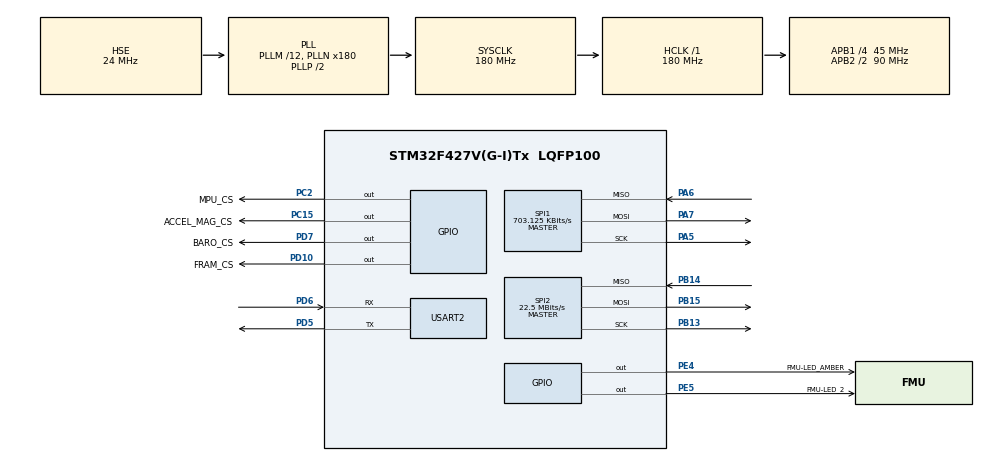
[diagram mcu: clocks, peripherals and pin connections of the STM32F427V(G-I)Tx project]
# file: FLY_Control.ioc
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Mcu.Family=STM32F4
Mcu.Name=STM32F427V(G-I)Tx
Mcu.Package=LQFP100
NVIC.PriorityGroup=NVIC_PRIORITYGROUP_4
PA13.Mode=Serial_Wire
PA13.Signal=SYS_JTMS-SWDIO
PA14.Mode=Serial_Wire
PA14.Signal=SYS_JTCK-SWCLK
PA5.Mode=Full_Duplex_Master
PA5.Signal=SPI1_SCK
PA6.Mode=Full_Duplex_Master
PA6.Signal=SPI1_MISO
PA7.Mode=Full_Duplex_Master
PA7.Signal=SPI1_MOSI
PB13.Mode=Full_Duplex_Master
PB13.Signal=SPI2_SCK
PB14.Mode=Full_Duplex_Master
PB14.Signal=SPI2_MISO
PB15.Mode=Full_Duplex_Master
PB15.Signal=SPI2_MOSI
PC15/OSC32_OUT.GPIO_Label=ACCEL_MAG_CS
PC15/OSC32_OUT.Signal=GPIO_Output
PC2.GPIO_Label=MPU_CS
PC2.GPIO_Speed=GPIO_SPEED_FREQ_HIGH
PC2.Signal=GPIO_Output
PD10.GPIO_Label=FRAM_CS
PD10.GPIO_Speed=GPIO_SPEED_FREQ_HIGH
PD10.Signal=GPIO_Output
PD5.Mode=Asynchronous
PD5.Signal=USART2_TX
PD6.Mode=Asynchronous
PD6.Signal=USART2_RX
PD7.GPIO_Label=BARO_CS
PD7.GPIO_Speed=GPIO_SPEED_FREQ_HIGH
PD7.Signal=GPIO_Output
PE4.GPIO_Label=FMU-LED_AMBER
PE4.GPIO_PuPd=GPIO_NOPULL
PE4.Signal=GPIO_Output
PE5.GPIO_Label=FMU-LED_2
PE5.Signal=GPIO_Output
PH0/OSC_IN.Mode=HSE-External-Clock-Source
PH0/OSC_IN.Signal=RCC_OSC_IN
PH1/OSC_OUT.Mode=HSE-External-Clock-Source
PH1/OSC_OUT.Signal=RCC_OSC_OUT
ProjectManager.HeapSize=0x200
ProjectManager.StackSize=0x400
ProjectManager.TargetToolchain=MDK-ARM V5
RCC.48MHZClocksFreq_Value=90000000
RCC.AHBFreq_Value=180000000
RCC.APB1CLKDivider=RCC_HCLK_DIV4
RCC.APB1Freq_Value=45000000
RCC.APB1TimFreq_Value=90000000
RCC.APB2CLKDivider=RCC_HCLK_DIV2
RCC.APB2Freq_Value=90000000
RCC.APB2TimFreq_Value=180000000
RCC.CortexFreq_Value=180000000
RCC.HCLKFreq_Value=180000000
RCC.HSE_VALUE=24000000
RCC.HSI_VALUE=16000000
RCC.LSE_VALUE=32768
RCC.PLLM=12
RCC.PLLN=180
RCC.PLLSourceVirtual=RCC_PLLSOURCE_HSE
RCC.SYSCLKFreq_VALUE=180000000
RCC.SYSCLKSource=RCC_SYSCLKSOURCE_PLLCLK
RCC.VCOOutputFreq_Value=360000000
SPI1.BaudRatePrescaler=SPI_BAUDRATEPRESCALER_128
SPI1.CalculateBaudRate=703.125 KBits/s
SPI1.Direction=SPI_DIRECTION_2LINES
SPI1.Mode=SPI_MODE_MASTER
SPI1.VirtualType=VM_MASTER
SPI2.CalculateBaudRate=22.5 MBits/s
SPI2.Direction=SPI_DIRECTION_2LINES
SPI2.Mode=SPI_MODE_MASTER
SPI2.VirtualType=VM_MASTER
USART2.VirtualMode=VM_ASYNC
board=FLY_Control

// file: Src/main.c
/**
  ******************************************************************************
  * File Name          : main.c
  * Description        : Main program body
  ******************************************************************************
  ** This notice applies to any and all portions of this file
  * that are not between comment pairs USER CODE BEGIN and
  * USER CODE END. Other portions of this file, whether
  * inserted by the user or by software development tools
  * are owned by their respective copyright owners.
  *
  * COPYRIGHT(c) 2019 STMicroelectronics
  *
  * Redistribution and use in source and binary forms, with or without modification,
  * are permitted provided that the following conditions are met:
  *   1. Redistributions of source code must retain the above copyright notice,
  *      this list of conditions and the following disclaimer.
  *   2. Redistributions in binary form must reproduce the above copyright notice,
  *      this list of conditions and the following disclaimer in the documentation
  *      and/or other materials provided with the distribution.
  *   3. Neither the name of STMicroelectronics nor the names of its contributors
  *      may be used to endorse or promote products derived from this software
  *      without specific prior written permission.
  *
  * THIS SOFTWARE IS PROVIDED BY THE COPYRIGHT HOLDERS AND CONTRIBUTORS "AS IS"
  * AND ANY EXPRESS OR IMPLIED WARRANTIES, INCLUDING, BUT NOT LIMITED TO, THE
  * IMPLIED WARRANTIES OF MERCHANTABILITY AND FITNESS FOR A PARTICULAR PURPOSE ARE
  * DISCLAIMED. IN NO EVENT SHALL THE COPYRIGHT HOLDER OR CONTRIBUTORS BE LIABLE
  * FOR ANY DIRECT, INDIRECT, INCIDENTAL, SPECIAL, EXEMPLARY, OR CONSEQUENTIAL
  * DAMAGES (INCLUDING, BUT NOT LIMITED TO, PROCUREMENT OF SUBSTITUTE GOODS OR
  * SERVICES; LOSS OF USE, DATA, OR PROFITS; OR BUSINESS INTERRUPTION) HOWEVER
  * CAUSED AND ON ANY THEORY OF LIABILITY, WHETHER IN CONTRACT, STRICT LIABILITY,
  * OR TORT (INCLUDING NEGLIGENCE OR OTHERWISE) ARISING IN ANY WAY OUT OF THE USE
  * OF THIS SOFTWARE, EVEN IF ADVISED OF THE POSSIBILITY OF SUCH DAMAGE.
  *
  ******************************************************************************
  */

#include "main.h"
#include "stm32f4xx_hal.h"
#include "spi.h"
#include "usart.h"
#include "gpio.h"

/* USER CODE BEGIN Includes */
#include "sys.h"
/* USER CODE END Includes */

/* USER CODE BEGIN PV */
/* Private variables ---------------------------------------------------------*/

/* USER CODE END PV */

void SystemClock_Config(void);

/* USER CODE BEGIN PFP */
/* Private function prototypes -----------------------------------------------*/

/* USER CODE END PFP */

int main(void)
{

  /* MCU Configuration----------------------------------------------------------*/

  /* Reset of all peripherals, Initializes the Flash interface and the Systick. */
  HAL_Init();

  /* Configure the system clock */
  SystemClock_Config();

  /* Initialize all configured peripherals */
  MX_GPIO_Init();
  MX_SPI1_Init();
  MX_USART2_UART_Init();
  MX_SPI2_Init();

  /* Infinite loop */
  while (1)
  {

  /* USER CODE BEGIN 3 */
	  LED1 =~LED1;
	  LED2 =~LED2;
//	  HAL_GPIO_TogglePin(FMU_LED_AMBER_GPIO_Port,FMU_LED_AMBER_Pin);
//	  HAL_GPIO_TogglePin(FMU_LED_2_GPIO_Port,FMU_LED_2_Pin);
	  HAL_Delay(300);
//	  HAL_GPIO_TogglePin(FMU_LED_AMBER_GPIO_Port,FMU_LED_AMBER_Pin);
//	  HAL_GPIO_TogglePin(FMU_LED_2_GPIO_Port,FMU_LED_2_Pin);
//	  HAL_Delay(300);
  }
  /* USER CODE END 3 */

}

/** System Clock Configuration
*/
void SystemClock_Config(void)
{

  RCC_OscInitTypeDef RCC_OscInitStruct;
  RCC_ClkInitTypeDef RCC_ClkInitStruct;

    /**Configure the main internal regulator output voltage
    */
  __HAL_RCC_PWR_CLK_ENABLE();

  __HAL_PWR_VOLTAGESCALING_CONFIG(PWR_REGULATOR_VOLTAGE_SCALE1);

    /**Initializes the CPU, AHB and APB busses clocks
    */
  RCC_OscInitStruct.OscillatorType = RCC_OSCILLATORTYPE_HSE;
  RCC_OscInitStruct.HSEState = RCC_HSE_BYPASS;
  RCC_OscInitStruct.PLL.PLLState = RCC_PLL_ON;
  RCC_OscInitStruct.PLL.PLLSource = RCC_PLLSOURCE_HSE;
  RCC_OscInitStruct.PLL.PLLM = 12;
  RCC_OscInitStruct.PLL.PLLN = 180;
  RCC_OscInitStruct.PLL.PLLP = RCC_PLLP_DIV2;
  RCC_OscInitStruct.PLL.PLLQ = 4;
  if (HAL_RCC_OscConfig(&RCC_OscInitStruct) != HAL_OK)
  {
    _Error_Handler(__FILE__, __LINE__);
  }

    /**Activate the Over-Drive mode
    */
  if (HAL_PWREx_EnableOverDrive() != HAL_OK)
  {
    _Error_Handler(__FILE__, __LINE__);
  }

    /**Initializes the CPU, AHB and APB busses clocks
    */
  RCC_ClkInitStruct.ClockType = RCC_CLOCKTYPE_HCLK|RCC_CLOCKTYPE_SYSCLK
                              |RCC_CLOCKTYPE_PCLK1|RCC_CLOCKTYPE_PCLK2;
  RCC_ClkInitStruct.SYSCLKSource = RCC_SYSCLKSOURCE_PLLCLK;
  RCC_ClkInitStruct.AHBCLKDivider = RCC_SYSCLK_DIV1;
  RCC_ClkInitStruct.APB1CLKDivider = RCC_HCLK_DIV4;
  RCC_ClkInitStruct.APB2CLKDivider = RCC_HCLK_DIV2;

  if (HAL_RCC_ClockConfig(&RCC_ClkInitStruct, FLASH_LATENCY_5) != HAL_OK)
  {
    _Error_Handler(__FILE__, __LINE__);
  }

    /**Configure the Systick interrupt time
    */
  HAL_SYSTICK_Config(HAL_RCC_GetHCLKFreq()/1000);

    /**Configure the Systick
    */
  HAL_SYSTICK_CLKSourceConfig(SYSTICK_CLKSOURCE_HCLK);

  /* SysTick_IRQn interrupt configuration */
  HAL_NVIC_SetPriority(SysTick_IRQn, 0, 0);
}

void _Error_Handler(char * file, int line)
{
  while(1)
  {
  }
}

/************************ (C) COPYRIGHT STMicroelectronics *****END OF FILE****/
